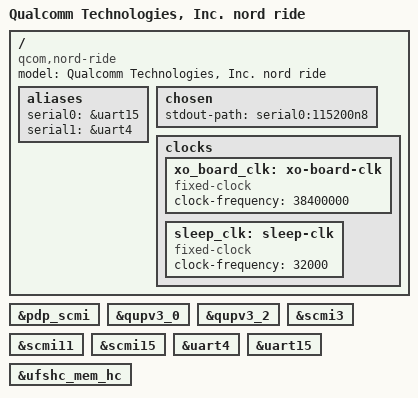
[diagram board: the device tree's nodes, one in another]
// SPDX-License-Identifier: BSD-3-Clause
/*
 * Copyright (c) Qualcomm Technologies, Inc. and/or its subsidiaries.
 */

/dts-v1/;

#include "nord-auto.dtsi"

/ {
	model = "Qualcomm Technologies, Inc. nord ride";
	compatible = "qcom,nord-ride", "qcom,nord";

	aliases {
		serial0 = &uart15;
		serial1 = &uart4;
	};

	chosen {
		stdout-path = "serial0:115200n8";
	};

	clocks {
		xo_board_clk: xo-board-clk {
			compatible = "fixed-clock";
			clock-frequency = <38400000>;
			#clock-cells = <0>;
		};

		sleep_clk: sleep-clk {
			compatible = "fixed-clock";
			clock-frequency = <32000>;
			#clock-cells = <0>;
		};
	};
};

&pdp_scmi {
	status = "okay";
};

&qupv3_0 {
	status = "okay";
};

&qupv3_2 {
	status = "okay";
};

&scmi3 {
	status = "okay";
};

&scmi11 {
	status = "okay";
};

&scmi15 {
	status = "okay";
};

&uart4 {
	status = "okay";
};

&uart15 {
	status = "okay";
};

&ufshc_mem_hc {
	status = "okay";
};
